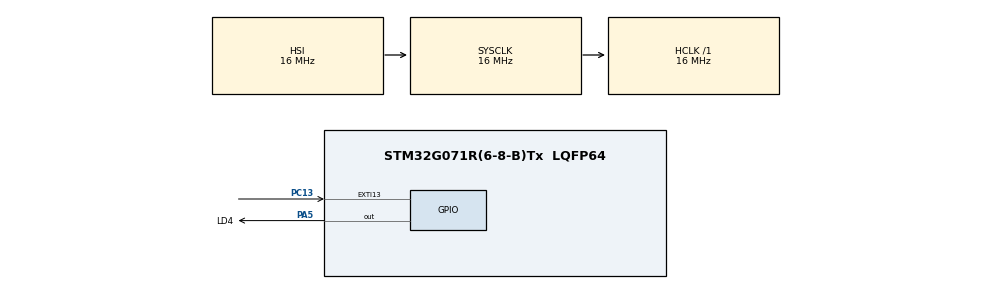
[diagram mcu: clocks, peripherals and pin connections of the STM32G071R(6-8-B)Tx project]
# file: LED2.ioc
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Mcu.Family=STM32G0
Mcu.Name=STM32G071R(6-8-B)Tx
Mcu.Package=LQFP64
NVIC.EXTI4_15_IRQn=true\:0\:0\:false\:false\:true\:true\:true
PA5.GPIO_Label=LD4
PA5.Signal=GPIO_Output
PC13.GPIO_ModeDefaultEXTI=GPIO_MODE_IT_FALLING
PC13.Signal=GPXTI13
ProjectManager.HeapSize=0x200
ProjectManager.StackSize=0x400
ProjectManager.TargetToolchain=MDK-ARM V5.27
RCC.AHBFreq_Value=16000000
RCC.CortexFreq_Value=16000000
RCC.EXTERNAL_CLOCK_VALUE=48000
RCC.HCLKFreq_Value=16000000
RCC.HSE_VALUE=8000000
RCC.HSI_VALUE=16000000
RCC.LSE_VALUE=32768
RCC.SYSCLKFreq_VALUE=16000000
RCC.VCOOutputFreq_Value=128000000
VP_SYS_VS_DBSignals.Mode=DisableDeadBatterySignals
board=custom

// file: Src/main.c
/* USER CODE BEGIN Header */
/**
  ******************************************************************************
  * @file           : main.c
  * @brief          : Main program body
  ******************************************************************************
  * @attention
  *
  * <h2><center>&copy; Copyright (c) 2021 STMicroelectronics.
  * All rights reserved.</center></h2>
  *
  * This software component is licensed by ST under BSD 3-Clause license,
  * the "License"; You may not use this file except in compliance with the
  * License. You may obtain a copy of the License at:
  *                        opensource.org/licenses/BSD-3-Clause
  *
  ******************************************************************************
  */
/* USER CODE END Header */
#include "main.h"
#include "gpio.h"

void SystemClock_Config(void);

int main(void)
{

  /* MCU Configuration--------------------------------------------------------*/

  /* Reset of all peripherals, Initializes the Flash interface and the Systick. */
  HAL_Init();

  /* Configure the system clock */
  SystemClock_Config();

  /* Initialize all configured peripherals */
  MX_GPIO_Init();

  /* Infinite loop */
  while (1)
  {

  }
}

void SystemClock_Config(void)
{
  RCC_OscInitTypeDef RCC_OscInitStruct = {0};
  RCC_ClkInitTypeDef RCC_ClkInitStruct = {0};

  /** Configure the main internal regulator output voltage
  */
  HAL_PWREx_ControlVoltageScaling(PWR_REGULATOR_VOLTAGE_SCALE1);
  /** Initializes the RCC Oscillators according to the specified parameters
  * in the RCC_OscInitTypeDef structure.
  */
  RCC_OscInitStruct.OscillatorType = RCC_OSCILLATORTYPE_HSI;
  RCC_OscInitStruct.HSIState = RCC_HSI_ON;
  RCC_OscInitStruct.HSIDiv = RCC_HSI_DIV1;
  RCC_OscInitStruct.HSICalibrationValue = RCC_HSICALIBRATION_DEFAULT;
  RCC_OscInitStruct.PLL.PLLState = RCC_PLL_NONE;
  if (HAL_RCC_OscConfig(&RCC_OscInitStruct) != HAL_OK)
  {
    Error_Handler();
  }
  /** Initializes the CPU, AHB and APB buses clocks
  */
  RCC_ClkInitStruct.ClockType = RCC_CLOCKTYPE_HCLK|RCC_CLOCKTYPE_SYSCLK
                              |RCC_CLOCKTYPE_PCLK1;
  RCC_ClkInitStruct.SYSCLKSource = RCC_SYSCLKSOURCE_HSI;
  RCC_ClkInitStruct.AHBCLKDivider = RCC_SYSCLK_DIV1;
  RCC_ClkInitStruct.APB1CLKDivider = RCC_HCLK_DIV1;

  if (HAL_RCC_ClockConfig(&RCC_ClkInitStruct, FLASH_LATENCY_0) != HAL_OK)
  {
    Error_Handler();
  }
}

/* USER CODE BEGIN 4 */

//********************************************************

void HAL_GPIO_EXTI_Falling_Callback(uint16_t GPIO_Pin)
{
	if(GPIO_Pin == GPIO_PIN_13)
	{
	  HAL_GPIO_TogglePin(LD4_GPIO_Port,LD4_Pin);
	}
}

/* USER CODE END 4 */

void Error_Handler(void)
{
  __disable_irq();
  while (1)
  {
  }
}

/************************ (C) COPYRIGHT STMicroelectronics *****END OF FILE****/
